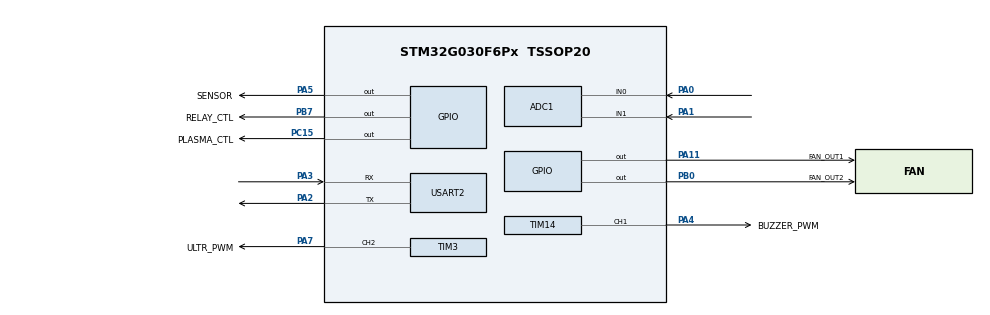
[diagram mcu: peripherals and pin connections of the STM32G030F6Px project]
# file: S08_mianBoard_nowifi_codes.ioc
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ADC1.Channel-0\#ChannelRegularConversion=ADC_CHANNEL_0
ADC1.NbrOfConversionFlag=1
ADC1.Rank-0\#ChannelRegularConversion=1
ADC1.SamplingTime-0\#ChannelRegularConversion=ADC_SAMPLINGTIME_COMMON_1
ADC1.SelectedChannel=ADC_CHANNEL_0|ADC_CHANNEL_1
ADC1.master=1
Dma.ADC1.1.Direction=DMA_PERIPH_TO_MEMORY
Dma.ADC1.1.EventEnable=DISABLE
Dma.ADC1.1.Instance=DMA1_Channel2
Dma.ADC1.1.MemDataAlignment=DMA_MDATAALIGN_HALFWORD
Dma.ADC1.1.MemInc=DMA_MINC_ENABLE
Dma.ADC1.1.Mode=DMA_NORMAL
Dma.ADC1.1.PeriphDataAlignment=DMA_PDATAALIGN_HALFWORD
Dma.ADC1.1.PeriphInc=DMA_PINC_DISABLE
Dma.ADC1.1.Polarity=HAL_DMAMUX_REQ_GEN_RISING
Dma.ADC1.1.Priority=DMA_PRIORITY_LOW
Dma.ADC1.1.RequestNumber=1
Dma.ADC1.1.SignalID=NONE
Dma.ADC1.1.SyncEnable=DISABLE
Dma.ADC1.1.SyncPolarity=HAL_DMAMUX_SYNC_NO_EVENT
Dma.ADC1.1.SyncRequestNumber=1
Dma.ADC1.1.SyncSignalID=NONE
Dma.Request0=USART2_TX
Dma.Request1=ADC1
Dma.USART2_TX.0.Direction=DMA_MEMORY_TO_PERIPH
Dma.USART2_TX.0.EventEnable=DISABLE
Dma.USART2_TX.0.Instance=DMA1_Channel1
Dma.USART2_TX.0.MemDataAlignment=DMA_MDATAALIGN_BYTE
Dma.USART2_TX.0.MemInc=DMA_MINC_ENABLE
Dma.USART2_TX.0.Mode=DMA_NORMAL
Dma.USART2_TX.0.PeriphDataAlignment=DMA_PDATAALIGN_BYTE
Dma.USART2_TX.0.PeriphInc=DMA_PINC_DISABLE
Dma.USART2_TX.0.Polarity=HAL_DMAMUX_REQ_GEN_RISING
Dma.USART2_TX.0.Priority=DMA_PRIORITY_LOW
Dma.USART2_TX.0.RequestNumber=1
Dma.USART2_TX.0.SignalID=NONE
Dma.USART2_TX.0.SyncEnable=DISABLE
Dma.USART2_TX.0.SyncPolarity=HAL_DMAMUX_SYNC_NO_EVENT
Dma.USART2_TX.0.SyncRequestNumber=1
Dma.USART2_TX.0.SyncSignalID=NONE
Mcu.Family=STM32G0
Mcu.Name=STM32G030F6Px
Mcu.Package=TSSOP20
NVIC.DMA1_Channel1_IRQn=true\:0\:0\:false\:false\:true\:false\:false\:true\:true
NVIC.DMA1_Channel2_3_IRQn=true\:0\:0\:false\:false\:true\:true\:false\:true\:true
NVIC.TIM16_IRQn=true\:3\:0\:false\:false\:true\:false\:false\:true\:true
NVIC.TIM17_IRQn=true\:0\:0\:false\:false\:true\:false\:true\:true\:true
NVIC.TimeBase=TIM16_IRQn
NVIC.TimeBaseIP=TIM16
NVIC.USART2_IRQn=true\:0\:0\:false\:false\:true\:false\:false\:true\:true
PA0.Mode=IN0
PA0.Signal=ADC1_IN0
PA1.Mode=IN1
PA1.Signal=ADC1_IN1
PA11\ [PA9].GPIO_Label=FAN_OUT1
PA11\ [PA9].Signal=GPIO_Output
PA13.Mode=Serial_Wire
PA13.Signal=SYS_SWDIO
PA14-BOOT0.Mode=Serial_Wire
PA14-BOOT0.Signal=SYS_SWCLK
PA14-BOOT0__PA15.StandardMode=true
PA2.Mode=Asynchronous
PA2.Signal=USART2_TX
PA3.Mode=Asynchronous
PA3.Signal=USART2_RX
PA4.GPIO_Label=BUZZER_PWM
PA4.Signal=S_TIM14_CH1
PA5.GPIO_Label=SENSOR
PA5.Signal=GPIO_Output
PA7.GPIO_Label=ULTR_PWM
PA7.Signal=S_TIM3_CH2
PB0.GPIO_Label=FAN_OUT2
PB0.Signal=GPIO_Output
PB0__PB1__PB2__PA8.StandardMode=true
PB3__PB4__PB5__PB6.StandardMode=true
PB7.GPIO_Label=RELAY_CTL
PB7.Signal=GPIO_Output
PB7__PB8.StandardMode=true
PC14-OSC32_IN\ (PC14)__PB9.StandardMode=true
PC15-OSC32_OUT\ (PC15).GPIO_Label=PLASMA_CTL
PC15-OSC32_OUT\ (PC15).Signal=GPIO_Output
ProjectManager.HeapSize=0x200
ProjectManager.StackSize=0x400
ProjectManager.TargetToolchain=MDK-ARM V5.32
RCC.ADCFreq_Value=64000000
RCC.AHBFreq_Value=64000000
RCC.CortexFreq_Value=64000000
RCC.EXTERNAL_CLOCK_VALUE=12288000
RCC.HCLKFreq_Value=64000000
RCC.HSE_VALUE=8000000
RCC.HSI_VALUE=16000000
RCC.LSE_VALUE=32768
RCC.SYSCLKFreq_VALUE=64000000
RCC.SYSCLKSource=RCC_SYSCLKSOURCE_PLLCLK
RCC.VCOOutputFreq_Value=128000000
SH.S_TIM14_CH1.0=TIM14_CH1,PWM Generation1 CH1
SH.S_TIM3_CH2.0=TIM3_CH2,PWM Generation2 CH2
STMicroelectronics.X-CUBE-AZRTOS-G0.1.1.0.ThreadXCcRTOSJjThreadXJjCore=true
STMicroelectronics.X-CUBE-AZRTOS-G0.1.1.0_IsAnAzureRtosMw=true
TIM14.Channel=TIM_CHANNEL_1
TIM3.Channel-PWM\ Generation2\ CH2=TIM_CHANNEL_2
USART2.VirtualMode-Asynchronous=VM_ASYNC
VP_IWDG_VS_IWDG.Mode=IWDG_Activate
VP_STMicroelectronics.X-CUBE-AZRTOS-G0_VS_RTOSJjThreadX_6.1.10_1.1.0.Mode=RTOSJjThreadX
VP_SYS_VS_tim16.Mode=TIM16
VP_TIM14_VS_ClockSourceINT.Mode=Enable_Timer
VP_TIM17_VS_ClockSourceINT.Mode=Enable_Timer
VP_TIM3_VS_ClockSourceINT.Mode=Internal
board=custom

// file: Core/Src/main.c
/* USER CODE BEGIN Header */
/**
  ******************************************************************************
  * @file           : main.c
  * @brief          : Main program body
  ******************************************************************************
  * @attention
  *
  * UDY_01 Version : 01 .DATA.2025.0610
  *
  *
  *
  *
  *
  *
  ******************************************************************************
  */
/* USER CODE END Header */
#include "app_threadx.h"
#include "main.h"
#include "adc.h"
#include "dma.h"
#include "iwdg.h"
#include "tim.h"
#include "usart.h"
#include "gpio.h"

/* USER CODE BEGIN Includes */
#include "bsp.h"
/* USER CODE END Includes */

void SystemClock_Config(void);

int main(void)
{

  /* MCU Configuration--------------------------------------------------------*/

  /* Reset of all peripherals, Initializes the Flash interface and the Systick. */
  HAL_Init();

  /* Configure the system clock */
  SystemClock_Config();

  /* Initialize all configured peripherals */
  MX_GPIO_Init();
  MX_DMA_Init();
  MX_ADC1_Init();
  MX_USART2_UART_Init();
  MX_TIM3_Init();
  MX_TIM14_Init();
  MX_TIM17_Init();
  MX_IWDG_Init();
  /* USER CODE BEGIN 2 */

    bsp_init();
    tx_kernel_enter();
  /* USER CODE END 2 */

   //MX_ThreadX_Init();

  /* We should never get here as control is now taken by the scheduler */

  /* Infinite loop */
  while (1)
  {

  }
}

void SystemClock_Config(void)
{
  LL_FLASH_SetLatency(LL_FLASH_LATENCY_2);
  while(LL_FLASH_GetLatency() != LL_FLASH_LATENCY_2)
  {
  }

  /* HSI configuration and activation */
  LL_RCC_HSI_Enable();
  while(LL_RCC_HSI_IsReady() != 1)
  {
  }

  /* LSI configuration and activation */
  LL_RCC_LSI_Enable();
  while(LL_RCC_LSI_IsReady() != 1)
  {
  }

  /* Main PLL configuration and activation */
  LL_RCC_PLL_ConfigDomain_SYS(LL_RCC_PLLSOURCE_HSI, LL_RCC_PLLM_DIV_1, 8, LL_RCC_PLLR_DIV_2);
  LL_RCC_PLL_Enable();
  LL_RCC_PLL_EnableDomain_SYS();
  while(LL_RCC_PLL_IsReady() != 1)
  {
  }

  /* Set AHB prescaler*/
  LL_RCC_SetAHBPrescaler(LL_RCC_SYSCLK_DIV_1);

  /* Sysclk activation on the main PLL */
  LL_RCC_SetSysClkSource(LL_RCC_SYS_CLKSOURCE_PLL);
  while(LL_RCC_GetSysClkSource() != LL_RCC_SYS_CLKSOURCE_STATUS_PLL)
  {
  }

  /* Set APB1 prescaler*/
  LL_RCC_SetAPB1Prescaler(LL_RCC_APB1_DIV_1);
  /* Update CMSIS variable (which can be updated also through SystemCoreClockUpdate function) */
  LL_SetSystemCoreClock(64000000);

   /* Update the time base */
  if (HAL_InitTick (TICK_INT_PRIORITY) != HAL_OK)
  {
    Error_Handler();
  }
}

void HAL_TIM_PeriodElapsedCallback(TIM_HandleTypeDef *htim)
{
  if (htim->Instance == TIM16)
  {
    HAL_IncTick();
  }
}

void Error_Handler(void)
{
  __disable_irq();
  while (1)
  {
  }
}
